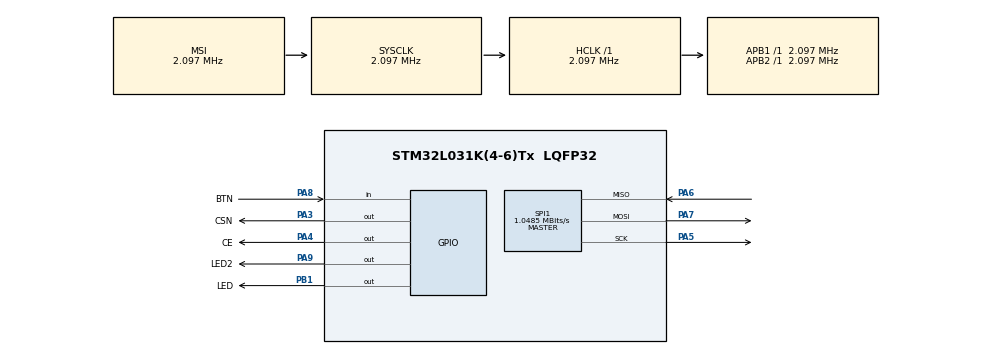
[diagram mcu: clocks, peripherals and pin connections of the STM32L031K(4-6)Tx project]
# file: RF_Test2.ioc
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Mcu.Family=STM32L0
Mcu.Name=STM32L031K(4-6)Tx
Mcu.Package=LQFP32
PA3.GPIO_Label=CSN
PA3.GPIO_Speed=GPIO_SPEED_FREQ_HIGH
PA3.PinState=GPIO_PIN_SET
PA3.Signal=GPIO_Output
PA4.GPIO_Label=CE
PA4.GPIO_Speed=GPIO_SPEED_FREQ_HIGH
PA4.Signal=GPIO_Output
PA5.Mode=Full_Duplex_Master
PA5.Signal=SPI1_SCK
PA6.Mode=Full_Duplex_Master
PA6.Signal=SPI1_MISO
PA7.Mode=Full_Duplex_Master
PA7.Signal=SPI1_MOSI
PA8.GPIO_Label=BTN
PA8.GPIO_PuPd=GPIO_PULLUP
PA8.Signal=GPIO_Input
PA9.GPIO_Label=LED2
PA9.Signal=GPIO_Output
PB1.GPIO_Label=LED
PB1.Signal=GPIO_Output
ProjectManager.HeapSize=0x200
ProjectManager.StackSize=0x400
ProjectManager.TargetToolchain=STM32CubeIDE
RCC.AHBFreq_Value=2097000
RCC.APB1Freq_Value=2097000
RCC.APB1TimFreq_Value=2097000
RCC.APB2Freq_Value=2097000
RCC.APB2TimFreq_Value=2097000
RCC.HSE_VALUE=8000000
RCC.HSI16_VALUE=16000000
RCC.HSI_VALUE=16000000
RCC.LSE_VALUE=32768
RCC.MSI_VALUE=2097000
RCC.SYSCLKFreq_VALUE=2097000
RCC.VCOOutputFreq_Value=48000000
SPI1.BaudRatePrescaler=SPI_BAUDRATEPRESCALER_2
SPI1.CalculateBaudRate=1.0485 MBits/s
SPI1.Direction=SPI_DIRECTION_2LINES
SPI1.Mode=SPI_MODE_MASTER
SPI1.VirtualType=VM_MASTER
board=custom

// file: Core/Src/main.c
/* USER CODE BEGIN Header */
/**
  ******************************************************************************
  * @file           : main.c
  * @brief          : Main program body
  ******************************************************************************
  * @attention
  *
  * Copyright (c) 2025 STMicroelectronics.
  * All rights reserved.
  *
  * This software is licensed under terms that can be found in the LICENSE file
  * in the root directory of this software component.
  * If no LICENSE file comes with this software, it is provided AS-IS.
  *
  ******************************************************************************
  */
/* USER CODE END Header */
#include "main.h"

/* USER CODE BEGIN Includes */
#include "nrf.h"
/* USER CODE END Includes */

SPI_HandleTypeDef hspi1;

void SystemClock_Config(void);
static void MX_GPIO_Init(void);
static void MX_SPI1_Init(void);

int main(void)
{

  /* MCU Configuration--------------------------------------------------------*/

  /* Reset of all peripherals, Initializes the Flash interface and the Systick. */
  HAL_Init();

  /* USER CODE BEGIN Init */
//#define TX
  /* USER CODE END Init */

  /* Configure the system clock */
  SystemClock_Config();

  /* Initialize all configured peripherals */
  MX_GPIO_Init();
  MX_SPI1_Init();
  /* USER CODE BEGIN 2 */
  nrf_reset();
#ifdef TX
  nrf_init(hspi1, 1);
#else
  nrf_init(hspi1, 0);
#endif
  uint8_t status;
  uint8_t payload;
  uint8_t ack_payload;
  /* USER CODE END 2 */

  /* Infinite loop */
  while (1)
  {
#ifdef TX
	  if(HAL_GPIO_ReadPin(BTN_GPIO_Port, BTN_Pin)) {
		  payload = 0b10111011;
		  HAL_GPIO_WritePin(LED_GPIO_Port, LED_Pin, 1);
	  } else {
		  payload = 0b11011101;
		  HAL_GPIO_WritePin(LED_GPIO_Port, LED_Pin, 0);
	  }
	  status = nrf_tx(&payload);
	  status = nrf_rx(&ack_payload);
	  if(ack_payload == 0b10111011)
	  	  HAL_GPIO_WritePin(LED2_GPIO_Port, LED2_Pin, 1);
	  else
	  	  HAL_GPIO_WritePin(LED2_GPIO_Port, LED2_Pin, 0);

#else
	  status = nrf_rx(&payload);
	  if(payload == 0b10111011)
		  HAL_GPIO_WritePin(LED_GPIO_Port, LED_Pin, 1);
	  else
		  HAL_GPIO_WritePin(LED_GPIO_Port, LED_Pin, 0);

	  if(HAL_GPIO_ReadPin(BTN_GPIO_Port, BTN_Pin)) {
	  	 ack_payload = 0b10111011;
	     HAL_GPIO_WritePin(LED2_GPIO_Port, LED2_Pin, 1);
	  } else {
	  	 ack_payload = 0b11011101;
	  	 HAL_GPIO_WritePin(LED2_GPIO_Port, LED2_Pin, 0);
	  }
	  status = nrf_tx(&ack_payload);
#endif
  }
}

void SystemClock_Config(void)
{
  RCC_OscInitTypeDef RCC_OscInitStruct = {0};
  RCC_ClkInitTypeDef RCC_ClkInitStruct = {0};

  /** Configure the main internal regulator output voltage
  */
  __HAL_PWR_VOLTAGESCALING_CONFIG(PWR_REGULATOR_VOLTAGE_SCALE1);

  /** Initializes the RCC Oscillators according to the specified parameters
  * in the RCC_OscInitTypeDef structure.
  */
  RCC_OscInitStruct.OscillatorType = RCC_OSCILLATORTYPE_MSI;
  RCC_OscInitStruct.MSIState = RCC_MSI_ON;
  RCC_OscInitStruct.MSICalibrationValue = 0;
  RCC_OscInitStruct.MSIClockRange = RCC_MSIRANGE_5;
  RCC_OscInitStruct.PLL.PLLState = RCC_PLL_NONE;
  if (HAL_RCC_OscConfig(&RCC_OscInitStruct) != HAL_OK)
  {
    Error_Handler();
  }

  /** Initializes the CPU, AHB and APB buses clocks
  */
  RCC_ClkInitStruct.ClockType = RCC_CLOCKTYPE_HCLK|RCC_CLOCKTYPE_SYSCLK
                              |RCC_CLOCKTYPE_PCLK1|RCC_CLOCKTYPE_PCLK2;
  RCC_ClkInitStruct.SYSCLKSource = RCC_SYSCLKSOURCE_MSI;
  RCC_ClkInitStruct.AHBCLKDivider = RCC_SYSCLK_DIV1;
  RCC_ClkInitStruct.APB1CLKDivider = RCC_HCLK_DIV1;
  RCC_ClkInitStruct.APB2CLKDivider = RCC_HCLK_DIV1;

  if (HAL_RCC_ClockConfig(&RCC_ClkInitStruct, FLASH_LATENCY_0) != HAL_OK)
  {
    Error_Handler();
  }
}

static void MX_SPI1_Init(void)
{

  /* SPI1 parameter configuration*/
  hspi1.Instance = SPI1;
  hspi1.Init.Mode = SPI_MODE_MASTER;
  hspi1.Init.Direction = SPI_DIRECTION_2LINES;
  hspi1.Init.DataSize = SPI_DATASIZE_8BIT;
  hspi1.Init.CLKPolarity = SPI_POLARITY_LOW;
  hspi1.Init.CLKPhase = SPI_PHASE_1EDGE;
  hspi1.Init.NSS = SPI_NSS_SOFT;
  hspi1.Init.BaudRatePrescaler = SPI_BAUDRATEPRESCALER_2;
  hspi1.Init.FirstBit = SPI_FIRSTBIT_MSB;
  hspi1.Init.TIMode = SPI_TIMODE_DISABLE;
  hspi1.Init.CRCCalculation = SPI_CRCCALCULATION_DISABLE;
  hspi1.Init.CRCPolynomial = 7;
  if (HAL_SPI_Init(&hspi1) != HAL_OK)
  {
    Error_Handler();
  }

}

static void MX_GPIO_Init(void)
{
  GPIO_InitTypeDef GPIO_InitStruct = {0};

  /* GPIO Ports Clock Enable */
  __HAL_RCC_GPIOA_CLK_ENABLE();
  __HAL_RCC_GPIOB_CLK_ENABLE();

  /*Configure GPIO pin Output Level */
  HAL_GPIO_WritePin(CSN_GPIO_Port, CSN_Pin, GPIO_PIN_SET);

  /*Configure GPIO pin Output Level */
  HAL_GPIO_WritePin(GPIOA, CE_Pin|LED2_Pin, GPIO_PIN_RESET);

  /*Configure GPIO pin Output Level */
  HAL_GPIO_WritePin(LED_GPIO_Port, LED_Pin, GPIO_PIN_RESET);

  /*Configure GPIO pins : CSN_Pin CE_Pin */
  GPIO_InitStruct.Pin = CSN_Pin|CE_Pin;
  GPIO_InitStruct.Mode = GPIO_MODE_OUTPUT_PP;
  GPIO_InitStruct.Pull = GPIO_NOPULL;
  GPIO_InitStruct.Speed = GPIO_SPEED_FREQ_HIGH;
  HAL_GPIO_Init(GPIOA, &GPIO_InitStruct);

  /*Configure GPIO pin : LED_Pin */
  GPIO_InitStruct.Pin = LED_Pin;
  GPIO_InitStruct.Mode = GPIO_MODE_OUTPUT_PP;
  GPIO_InitStruct.Pull = GPIO_NOPULL;
  GPIO_InitStruct.Speed = GPIO_SPEED_FREQ_LOW;
  HAL_GPIO_Init(LED_GPIO_Port, &GPIO_InitStruct);

  /*Configure GPIO pin : BTN_Pin */
  GPIO_InitStruct.Pin = BTN_Pin;
  GPIO_InitStruct.Mode = GPIO_MODE_INPUT;
  GPIO_InitStruct.Pull = GPIO_PULLUP;
  HAL_GPIO_Init(BTN_GPIO_Port, &GPIO_InitStruct);

  /*Configure GPIO pin : LED2_Pin */
  GPIO_InitStruct.Pin = LED2_Pin;
  GPIO_InitStruct.Mode = GPIO_MODE_OUTPUT_PP;
  GPIO_InitStruct.Pull = GPIO_NOPULL;
  GPIO_InitStruct.Speed = GPIO_SPEED_FREQ_LOW;
  HAL_GPIO_Init(LED2_GPIO_Port, &GPIO_InitStruct);

}

void Error_Handler(void)
{
  __disable_irq();
  while (1)
  {
  }
}
